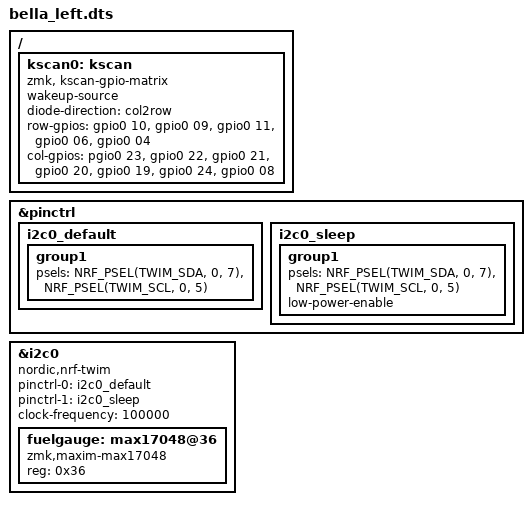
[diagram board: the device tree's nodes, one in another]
/*
 * Copyright (c) 2023 The ZMK Contributors
 *
 * SPDX-License-Identifier: MIT
 */

#include "bella.dtsi"

/{
kscan0: kscan {
    compatible = "zmk, kscan-gpio-matrix";
    wakeup-source;
    diode-direction = "col2row";
    row-gpios
        = <&gpio0 10 (GPIO_ACTIVE_HIGH | GPIO_PULL_DOWN)>
        , <&gpio0 09 (GPIO_ACTIVE_HIGH | GPIO_PULL_DOWN)>
        , <&gpio0 11 (GPIO_ACTIVE_HIGH | GPIO_PULL_DOWN)>
        , <&gpio0 06 (GPIO_ACTIVE_HIGH | GPIO_PULL_DOWN)>
        , <&gpio0 04 (GPIO_ACTIVE_HIGH | GPIO_PULL_DOWN)>
        ;
    col-gpios
        = <&pgio0 23 GPIO_ACTIVE_HIGH>
        , <&gpio0 22 GPIO_ACTIVE_HIGH>
        , <&gpio0 21 GPIO_ACTIVE_HIGH>
        , <&gpio0 20 GPIO_ACTIVE_HIGH>
        , <&gpio0 19 GPIO_ACTIVE_HIGH>
        , <&gpio0 24 GPIO_ACTIVE_HIGH>
        , <&gpio0 08 GPIO_ACTIVE_HIGH>
        ;
    };
};

&pinctrl {
     i2c0_default: i2c0_default {
        group1 {
        psels = <NRF_PSEL(TWIM_SDA, 0, 7)>,
                <NRF_PSEL(TWIM_SCL, 0, 5)>;
        };
    };
    i2c0_sleep: i2c0_sleep {
        group1 {
        psels = <NRF_PSEL(TWIM_SDA, 0, 7)>,
                <NRF_PSEL(TWIM_SCL, 0, 5)>;
        low-power-enable;
        };
    };
};

&i2c0 {
    status = "okay";
    compatible = "nordic,nrf-twim";
    pinctrl-0 = <&i2c0_default>;
    pinctrl-1 = <&i2c0_sleep>;
    pinctrl-names = "default", "sleep";
    clock-frequency = <100000>;

    fuelgauge: max17048@36 {
        compatible = "zmk,maxim-max17048";
        reg = <0x36>;
    };
};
